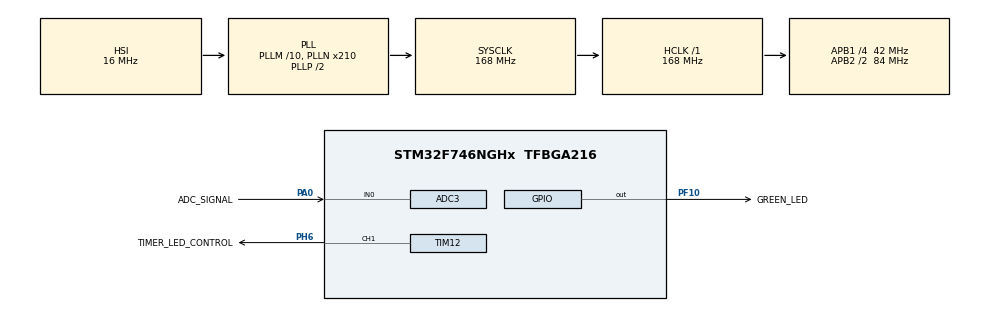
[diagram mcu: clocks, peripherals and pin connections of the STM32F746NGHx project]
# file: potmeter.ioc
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ADC3.Channel-0\#ChannelRegularConversion=ADC_CHANNEL_0
ADC3.NbrOfConversionFlag=1
ADC3.Rank-0\#ChannelRegularConversion=1
ADC3.SamplingTime-0\#ChannelRegularConversion=ADC_SAMPLETIME_3CYCLES
Mcu.Family=STM32F7
Mcu.Name=STM32F746NGHx
Mcu.Package=TFBGA216
NVIC.PriorityGroup=NVIC_PRIORITYGROUP_4
NVIC.TIM1_BRK_TIM9_IRQn=true\:1\:0\:true\:false\:true\:true\:true
NVIC.TIM5_IRQn=true\:1\:0\:true\:false\:true\:true\:true
NVIC.TIM8_TRG_COM_TIM14_IRQn=true\:0\:0\:false\:false\:true\:false\:true
NVIC.TimeBase=TIM8_TRG_COM_TIM14_IRQn
NVIC.TimeBaseIP=TIM14
PA0/WKUP.GPIO_Label=ADC_SIGNAL
PA0/WKUP.Signal=ADCx_IN0
PA13.Mode=Serial_Wire
PA13.Signal=SYS_JTMS-SWDIO
PA14.Mode=Serial_Wire
PA14.Signal=SYS_JTCK-SWCLK
PB4.Signal=S_TIM3_CH1
PC14/OSC32_IN.Mode=LSE-External-Oscillator
PC14/OSC32_IN.Signal=RCC_OSC32_IN
PC15/OSC32_OUT.Mode=LSE-External-Oscillator
PC15/OSC32_OUT.Signal=RCC_OSC32_OUT
PF10.GPIO_Label=GREEN_LED
PF10.Signal=GPIO_Output
PH0/OSC_IN.Mode=HSE-External-Clock-Source
PH0/OSC_IN.Signal=RCC_OSC_IN
PH1/OSC_OUT.Mode=HSE-External-Clock-Source
PH1/OSC_OUT.Signal=RCC_OSC_OUT
PH6.GPIO_Label=TIMER_LED_CONTROL
PH6.Signal=S_TIM12_CH1
ProjectManager.HeapSize=0x200
ProjectManager.StackSize=0x400
ProjectManager.TargetToolchain=STM32CubeIDE
RCC.AHBFreq_Value=168000000
RCC.APB1CLKDivider=RCC_HCLK_DIV4
RCC.APB1Freq_Value=42000000
RCC.APB1TimFreq_Value=84000000
RCC.APB2CLKDivider=RCC_HCLK_DIV2
RCC.APB2Freq_Value=84000000
RCC.APB2TimFreq_Value=168000000
RCC.CortexFreq_Value=168000000
RCC.HCLKFreq_Value=168000000
RCC.HSE_VALUE=25000000
RCC.HSI_VALUE=16000000
RCC.PLLM=10
RCC.PLLN=210
RCC.PLLSourceVirtual=RCC_PLLSOURCE_HSI
RCC.SYSCLKFreq_VALUE=168000000
RCC.SYSCLKSource=RCC_SYSCLKSOURCE_PLLCLK
RCC.USBFreq_Value=168000000
RCC.VCOOutputFreq_Value=336000000
SH.ADCx_IN0.0=ADC3_IN0,IN0
SH.S_TIM12_CH1.0=TIM12_CH1,PWM Generation1 CH1
SH.S_TIM3_CH1.0=TIM3_CH1
TIM12.Channel-PWM\ Generation1\ CH1=TIM_CHANNEL_1
TIM12.Period=4096-1
TIM5.Prescaler=8400
TIM9.AutoReloadPreload=TIM_AUTORELOAD_PRELOAD_ENABLE
TIM9.Period=5000
TIM9.Prescaler=16800
VP_SYS_VS_tim14.Mode=TIM14
VP_TIM5_VS_ClockSourceINT.Mode=Internal
VP_TIM9_VS_ClockSourceINT.Mode=Internal
board=STM32F746G-DISCO

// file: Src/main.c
/* USER CODE BEGIN Header */
/**
  ******************************************************************************
  * @file           : main.c
  * @brief          : Main program body
  ******************************************************************************
  * @attention
  *
  * <h2><center>&copy; Copyright (c) 2019 STMicroelectronics.
  * All rights reserved.</center></h2>
  *
  * This software component is licensed by ST under BSD 3-Clause license,
  * the "License"; You may not use this file except in compliance with the
  * License. You may obtain a copy of the License at:
  *                        opensource.org/licenses/BSD-3-Clause
  *
  ******************************************************************************
  */
/* USER CODE END Header */

#include "main.h"
#include "adc.h"
#include "tim.h"
#include "gpio.h"

/* USER CODE BEGIN PV */
uint16_t adc_value;
uint16_t change_timer5_period;
/* USER CODE END PV */

void SystemClock_Config(void);
/* USER CODE BEGIN PFP */
void dim_led(void);
void dim_led_with_potmeter(void);
uint16_t read_potmeter(void);
void flash_green_led(void);
/* USER CODE END PFP */

/* USER CODE BEGIN 0 */
void dim_led(void)
{
	int potmeter_cycle = 4095/2;
	for(int i = 0; i < potmeter_cycle; ++i){
		TIM12->CCR1 = i;
		HAL_Delay(1);
	}

	for(int i = potmeter_cycle; i > 0; --i){
		TIM12->CCR1 = i;
		HAL_Delay(1);
	}
}

uint16_t read_potmeter(void){

	  HAL_ADC_Start(&hadc3);
	  if (HAL_ADC_PollForConversion(&hadc3, 10) == HAL_OK) {
		  adc_value = HAL_ADC_GetValue(&hadc3);
	  }

	  change_timer5_period = 5000 - (int)((float)4500 / 4096 * adc_value);
	  TIM9->ARR = change_timer5_period;

	  return adc_value;
}

void dim_led_with_potmeter(void)
{
	TIM12->CCR1 = adc_value;
}

void flash_green_led(void)
{

	HAL_GPIO_WritePin( GREEN_LED_GPIO_Port,  GREEN_LED_Pin, 1);
}
/* USER CODE END 0 */

int main(void)
{

  /* MCU Configuration--------------------------------------------------------*/

  /* Reset of all peripherals, Initializes the Flash interface and the Systick. */
  HAL_Init();

  /* Configure the system clock */
  SystemClock_Config();

  /* Initialize all configured peripherals */
  MX_GPIO_Init();
  MX_ADC3_Init();
  MX_TIM12_Init();
  MX_TIM5_Init();
  MX_TIM9_Init();
  /* USER CODE BEGIN 2 */
  HAL_TIM_PWM_Start(&htim12, TIM_CHANNEL_1);
  HAL_TIM_Base_Start_IT(&htim9);
  /* USER CODE END 2 */

  /* Infinite loop */
  /* USER CODE BEGIN WHILE */
  while (1)
  {
	  //dim_led();
	  read_potmeter();
	  dim_led_with_potmeter();
	  //HAL_Delay(50);
	  //flash_green_led();

    /* USER CODE END WHILE */

  }
}

void SystemClock_Config(void)
{
  RCC_OscInitTypeDef RCC_OscInitStruct = {0};
  RCC_ClkInitTypeDef RCC_ClkInitStruct = {0};

  /** Configure LSE Drive Capability
  */
  HAL_PWR_EnableBkUpAccess();
  /** Configure the main internal regulator output voltage
  */
  __HAL_RCC_PWR_CLK_ENABLE();
  __HAL_PWR_VOLTAGESCALING_CONFIG(PWR_REGULATOR_VOLTAGE_SCALE2);
  /** Initializes the CPU, AHB and APB busses clocks
  */
  RCC_OscInitStruct.OscillatorType = RCC_OSCILLATORTYPE_HSI;
  RCC_OscInitStruct.HSIState = RCC_HSI_ON;
  RCC_OscInitStruct.HSICalibrationValue = RCC_HSICALIBRATION_DEFAULT;
  RCC_OscInitStruct.PLL.PLLState = RCC_PLL_ON;
  RCC_OscInitStruct.PLL.PLLSource = RCC_PLLSOURCE_HSI;
  RCC_OscInitStruct.PLL.PLLM = 10;
  RCC_OscInitStruct.PLL.PLLN = 210;
  RCC_OscInitStruct.PLL.PLLP = RCC_PLLP_DIV2;
  RCC_OscInitStruct.PLL.PLLQ = 2;
  if (HAL_RCC_OscConfig(&RCC_OscInitStruct) != HAL_OK)
  {
    Error_Handler();
  }
  /** Initializes the CPU, AHB and APB busses clocks
  */
  RCC_ClkInitStruct.ClockType = RCC_CLOCKTYPE_HCLK|RCC_CLOCKTYPE_SYSCLK
                              |RCC_CLOCKTYPE_PCLK1|RCC_CLOCKTYPE_PCLK2;
  RCC_ClkInitStruct.SYSCLKSource = RCC_SYSCLKSOURCE_PLLCLK;
  RCC_ClkInitStruct.AHBCLKDivider = RCC_SYSCLK_DIV1;
  RCC_ClkInitStruct.APB1CLKDivider = RCC_HCLK_DIV4;
  RCC_ClkInitStruct.APB2CLKDivider = RCC_HCLK_DIV2;

  if (HAL_RCC_ClockConfig(&RCC_ClkInitStruct, FLASH_LATENCY_5) != HAL_OK)
  {
    Error_Handler();
  }
}

void HAL_TIM_PeriodElapsedCallback(TIM_HandleTypeDef *htim)
{
  if (htim->Instance == TIM14) {
    HAL_IncTick();
  }
  /* USER CODE BEGIN Callback 1 */
  if(htim->Instance == TIM9) {

	  HAL_GPIO_TogglePin(GREEN_LED_GPIO_Port,  GREEN_LED_Pin);
  }

  /* USER CODE END Callback 1 */
}

void Error_Handler(void)
{
}

/************************ (C) COPYRIGHT STMicroelectronics *****END OF FILE****/
